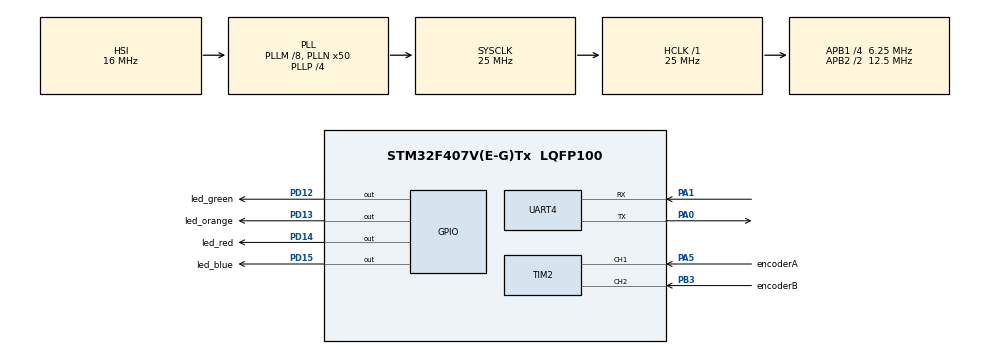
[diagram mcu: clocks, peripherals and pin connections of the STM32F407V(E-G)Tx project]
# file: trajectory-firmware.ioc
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FREERTOS.Tasks01=defaultTask,0,128,StartDefaultTask,Default,NULL,Dynamic,NULL,NULL;blink_task,-3,128,blink,Default,NULL,Dynamic,NULL,NULL
Mcu.Family=STM32F4
Mcu.Name=STM32F407V(E-G)Tx
Mcu.Package=LQFP100
NVIC.PriorityGroup=NVIC_PRIORITYGROUP_4
NVIC.TIM1_UP_TIM10_IRQn=true\:0\:0\:false\:false\:true\:false\:false\:true
NVIC.TimeBase=TIM1_UP_TIM10_IRQn
NVIC.TimeBaseIP=TIM1
PA0-WKUP.Mode=Asynchronous
PA0-WKUP.Signal=UART4_TX
PA1.Mode=Asynchronous
PA1.Signal=UART4_RX
PA13.Mode=Serial_Wire
PA13.Signal=SYS_JTMS-SWDIO
PA14.Mode=Serial_Wire
PA14.Signal=SYS_JTCK-SWCLK
PA5.GPIO_Label=encoderA
PA5.GPIO_PuPd=GPIO_PULLUP
PA5.Signal=S_TIM2_CH1_ETR
PB3.GPIO_Label=encoderB
PB3.GPIO_PuPd=GPIO_PULLUP
PB3.Signal=S_TIM2_CH2
PD12.GPIO_Label=led_green
PD12.GPIO_ModeDefaultOutputPP=GPIO_MODE_OUTPUT_PP
PD12.GPIO_PuPd=GPIO_PULLUP
PD12.PinState=GPIO_PIN_RESET
PD12.Signal=GPIO_Output
PD13.GPIO_Label=led_orange
PD13.GPIO_PuPd=GPIO_PULLUP
PD13.Signal=GPIO_Output
PD14.GPIO_Label=led_red
PD14.GPIO_PuPd=GPIO_PULLUP
PD14.Signal=GPIO_Output
PD15.GPIO_Label=led_blue
PD15.GPIO_PuPd=GPIO_PULLUP
PD15.Signal=GPIO_Output
ProjectManager.HeapSize=0x200
ProjectManager.StackSize=0x400
ProjectManager.TargetToolchain=SW4STM32
RCC.48MHZClocksFreq_Value=14285714.285714285
RCC.AHBFreq_Value=25000000
RCC.APB1CLKDivider=RCC_HCLK_DIV4
RCC.APB1Freq_Value=6250000
RCC.APB1TimFreq_Value=12500000
RCC.APB2CLKDivider=RCC_HCLK_DIV2
RCC.APB2Freq_Value=12500000
RCC.APB2TimFreq_Value=25000000
RCC.CortexFreq_Value=25000000
RCC.HCLKFreq_Value=25000000
RCC.HSE_VALUE=8000000
RCC.HSI_VALUE=16000000
RCC.LSE_VALUE=32768
RCC.PLLM=8
RCC.PLLN=50
RCC.PLLP=RCC_PLLP_DIV4
RCC.PLLQ=7
RCC.SYSCLKFreq_VALUE=25000000
RCC.SYSCLKSource=RCC_SYSCLKSOURCE_PLLCLK
RCC.VCOOutputFreq_Value=100000000
SH.S_TIM2_CH1_ETR.0=TIM2_CH1,Encoder_Interface
SH.S_TIM2_CH2.0=TIM2_CH2,Encoder_Interface
TIM2.EncoderMode=TIM_ENCODERMODE_TI12
UART4.VirtualMode=Asynchronous
VP_FREERTOS_VS_CMSIS_V1.Mode=CMSIS_V1
VP_SYS_VS_tim1.Mode=TIM1
board=STM32F4DISCOVERY

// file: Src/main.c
/* USER CODE BEGIN Header */
/**
  ******************************************************************************
  * @file           : main.c
  * @brief          : Main program body
  ******************************************************************************
  * @attention
  *
  * <h2><center>&copy; Copyright (c) 2019 STMicroelectronics.
  * All rights reserved.</center></h2>
  *
  * This software component is licensed by ST under BSD 3-Clause license,
  * the "License"; You may not use this file except in compliance with the
  * License. You may obtain a copy of the License at:
  *                        opensource.org/licenses/BSD-3-Clause
  *
  ******************************************************************************
  */
/* USER CODE END Header */

#include "main.h"
#include "cmsis_os.h"
#include "tim.h"
#include "usart.h"
#include "gpio.h"

/* USER CODE BEGIN PV */
int counter = 0;

/* USER CODE END PV */

void SystemClock_Config(void);
void MX_FREERTOS_Init(void);

int main(void)
{

  /* MCU Configuration--------------------------------------------------------*/

  /* Reset of all peripherals, Initializes the Flash interface and the Systick. */
  HAL_Init();

  /* Configure the system clock */
  SystemClock_Config();

  /* Initialize all configured peripherals */
  MX_GPIO_Init();
  MX_UART4_Init();
  MX_TIM2_Init();

  /* Call init function for freertos objects (in freertos.c) */
  MX_FREERTOS_Init();

  /* Start scheduler */
  osKernelStart();

  /* We should never get here as control is now taken by the scheduler */

  /* Infinite loop */
  while (1)
  {

    /* USER CODE BEGIN 3 */
	 /* counter = TIM2->CNT; */
  }
  /* USER CODE END 3 */
}

void SystemClock_Config(void)
{
  RCC_OscInitTypeDef RCC_OscInitStruct = {0};
  RCC_ClkInitTypeDef RCC_ClkInitStruct = {0};

  /** Configure the main internal regulator output voltage
  */
  __HAL_RCC_PWR_CLK_ENABLE();
  __HAL_PWR_VOLTAGESCALING_CONFIG(PWR_REGULATOR_VOLTAGE_SCALE1);
  /** Initializes the CPU, AHB and APB busses clocks
  */
  RCC_OscInitStruct.OscillatorType = RCC_OSCILLATORTYPE_HSI;
  RCC_OscInitStruct.HSIState = RCC_HSI_ON;
  RCC_OscInitStruct.HSICalibrationValue = RCC_HSICALIBRATION_DEFAULT;
  RCC_OscInitStruct.PLL.PLLState = RCC_PLL_ON;
  RCC_OscInitStruct.PLL.PLLSource = RCC_PLLSOURCE_HSI;
  RCC_OscInitStruct.PLL.PLLM = 8;
  RCC_OscInitStruct.PLL.PLLN = 50;
  RCC_OscInitStruct.PLL.PLLP = RCC_PLLP_DIV4;
  RCC_OscInitStruct.PLL.PLLQ = 7;
  if (HAL_RCC_OscConfig(&RCC_OscInitStruct) != HAL_OK)
  {
    Error_Handler();
  }
  /** Initializes the CPU, AHB and APB busses clocks
  */
  RCC_ClkInitStruct.ClockType = RCC_CLOCKTYPE_HCLK|RCC_CLOCKTYPE_SYSCLK
                              |RCC_CLOCKTYPE_PCLK1|RCC_CLOCKTYPE_PCLK2;
  RCC_ClkInitStruct.SYSCLKSource = RCC_SYSCLKSOURCE_PLLCLK;
  RCC_ClkInitStruct.AHBCLKDivider = RCC_SYSCLK_DIV1;
  RCC_ClkInitStruct.APB1CLKDivider = RCC_HCLK_DIV4;
  RCC_ClkInitStruct.APB2CLKDivider = RCC_HCLK_DIV2;

  if (HAL_RCC_ClockConfig(&RCC_ClkInitStruct, FLASH_LATENCY_0) != HAL_OK)
  {
    Error_Handler();
  }
}

void HAL_TIM_PeriodElapsedCallback(TIM_HandleTypeDef *htim)
{
  if (htim->Instance == TIM1) {
    HAL_IncTick();
  }
}

void Error_Handler(void)
{
}

/************************ (C) COPYRIGHT STMicroelectronics *****END OF FILE****/

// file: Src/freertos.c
/* USER CODE BEGIN Header */
/**
  ******************************************************************************
  * File Name          : freertos.c
  * Description        : Code for freertos applications
  ******************************************************************************
  * @attention
  *
  * <h2><center>&copy; Copyright (c) 2019 STMicroelectronics.
  * All rights reserved.</center></h2>
  *
  * This software component is licensed by ST under Ultimate Liberty license
  * SLA0044, the "License"; You may not use this file except in compliance with
  * the License. You may obtain a copy of the License at:
  *                             www.st.com/SLA0044
  *
  ******************************************************************************
  */
/* USER CODE END Header */

#include "FreeRTOS.h"
#include "task.h"
#include "main.h"
#include "cmsis_os.h"

osThreadId defaultTaskHandle;
osThreadId blink_taskHandle;

void StartDefaultTask(void const * argument);
void blink(void const * argument);

void MX_FREERTOS_Init(void); /* (MISRA C 2004 rule 8.1) */

void MX_FREERTOS_Init(void) {

  /* Create the thread(s) */
  /* definition and creation of defaultTask */
  osThreadDef(defaultTask, StartDefaultTask, osPriorityNormal, 0, 128);
  defaultTaskHandle = osThreadCreate(osThread(defaultTask), NULL);

  /* definition and creation of blink_task */
  osThreadDef(blink_task, blink, osPriorityIdle, 0, 128);
  blink_taskHandle = osThreadCreate(osThread(blink_task), NULL);

}

void StartDefaultTask(void const * argument)
{

  for(;;)
  {
    osDelay(1);
  }
}

void blink(void const * argument)
{
  /* USER CODE BEGIN blink */
  /* Infinite loop */
  for(;;)
  {
	HAL_GPIO_TogglePin(GPIOD, led_green_Pin);
    osDelay(337);
    HAL_GPIO_TogglePin(GPIOD, led_orange_Pin);
    osDelay(777);
    HAL_GPIO_TogglePin(GPIOD, led_red_Pin);
    osDelay(387);
    HAL_GPIO_TogglePin(GPIOD, led_blue_Pin);
    osDelay(591);

  }
  /* USER CODE END blink */
}

/************************ (C) COPYRIGHT STMicroelectronics *****END OF FILE****/
